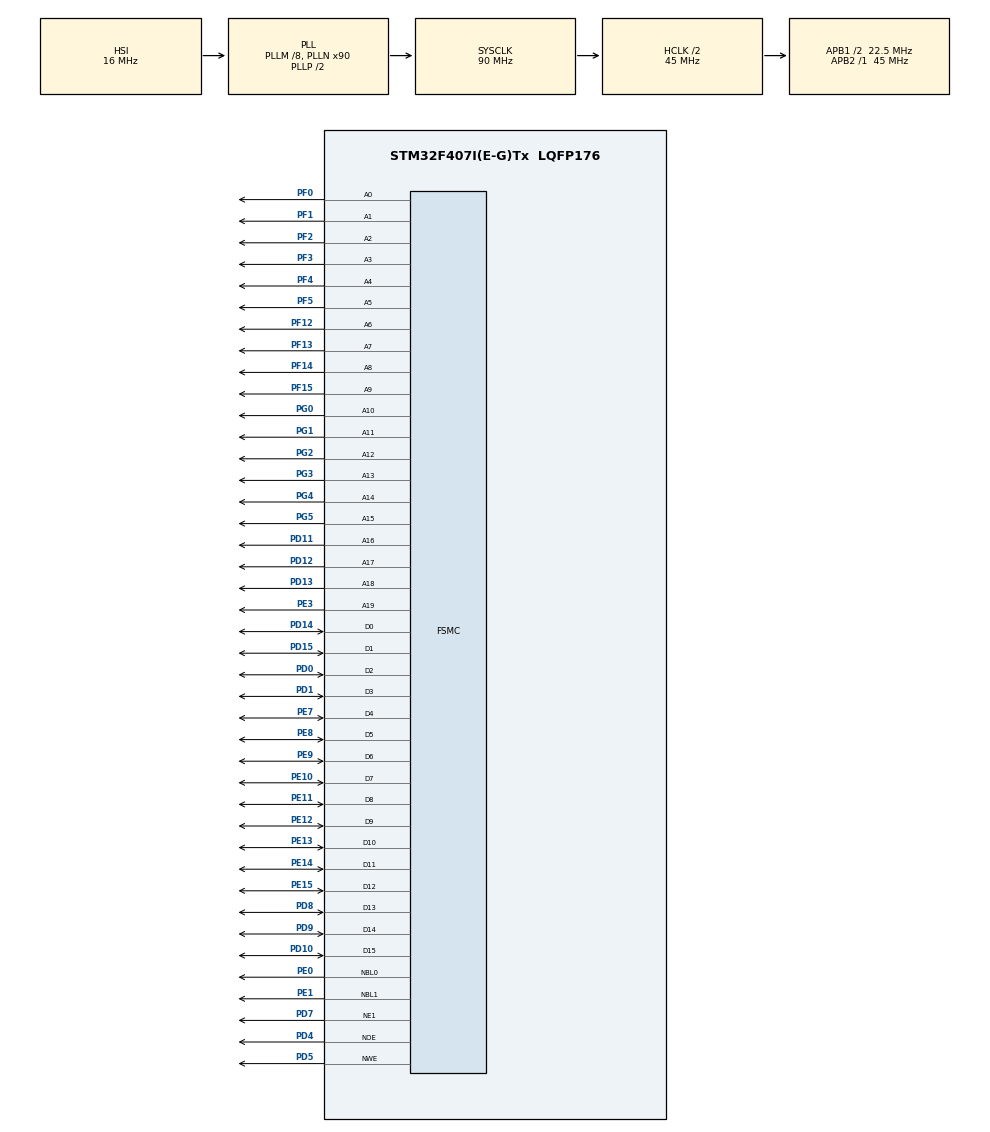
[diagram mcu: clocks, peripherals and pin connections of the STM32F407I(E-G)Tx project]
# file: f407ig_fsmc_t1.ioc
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FSMC.ExtendedMode1=FSMC_EXTENDED_MODE_DISABLE
FSMC.WriteOperation1=FSMC_WRITE_OPERATION_ENABLE
Mcu.Family=STM32F4
Mcu.Name=STM32F407I(E-G)Tx
Mcu.Package=LQFP176
NVIC.PriorityGroup=NVIC_PRIORITYGROUP_4
PA13.Mode=Trace_Asynchronous_SW
PA13.Signal=SYS_JTMS-SWDIO
PA14.Mode=Trace_Asynchronous_SW
PA14.Signal=SYS_JTCK-SWCLK
PB3.Mode=Trace_Asynchronous_SW
PB3.Signal=SYS_JTDO-SWO
PC14-OSC32_IN.Mode=LSE-External-Oscillator
PC14-OSC32_IN.Signal=RCC_OSC32_IN
PC15-OSC32_OUT.Mode=LSE-External-Oscillator
PC15-OSC32_OUT.Signal=RCC_OSC32_OUT
PD0.Signal=FSMC_D2_DA2
PD1.Signal=FSMC_D3_DA3
PD10.Signal=FSMC_D15_DA15
PD11.Signal=FSMC_A16_CLE
PD12.Signal=FSMC_A17_ALE
PD13.Signal=FSMC_A18
PD14.Signal=FSMC_D0_DA0
PD15.Signal=FSMC_D1_DA1
PD4.Signal=FSMC_NOE
PD5.Signal=FSMC_NWE
PD7.Mode=NorPsramChipSelect1_1
PD7.Signal=FSMC_NE1
PD8.Signal=FSMC_D13_DA13
PD9.Signal=FSMC_D14_DA14
PE0.Signal=FSMC_NBL0
PE1.Signal=FSMC_NBL1
PE10.Signal=FSMC_D7_DA7
PE11.Signal=FSMC_D8_DA8
PE12.Signal=FSMC_D9_DA9
PE13.Signal=FSMC_D10_DA10
PE14.Signal=FSMC_D11_DA11
PE15.Signal=FSMC_D12_DA12
PE3.Signal=FSMC_A19
PE7.Signal=FSMC_D4_DA4
PE8.Signal=FSMC_D5_DA5
PE9.Signal=FSMC_D6_DA6
PF0.Signal=FSMC_A0
PF1.Signal=FSMC_A1
PF12.Signal=FSMC_A6
PF13.Signal=FSMC_A7
PF14.Signal=FSMC_A8
PF15.Signal=FSMC_A9
PF2.Signal=FSMC_A2
PF3.Signal=FSMC_A3
PF4.Signal=FSMC_A4
PF5.Signal=FSMC_A5
PG0.Signal=FSMC_A10
PG1.Signal=FSMC_A11
PG2.Signal=FSMC_A12
PG3.Signal=FSMC_A13
PG4.Signal=FSMC_A14
PG5.Signal=FSMC_A15
PH0-OSC_IN.Mode=HSE-External-Oscillator
PH0-OSC_IN.Signal=RCC_OSC_IN
PH1-OSC_OUT.Mode=HSE-External-Oscillator
PH1-OSC_OUT.Signal=RCC_OSC_OUT
ProjectManager.HeapSize=0x200
ProjectManager.StackSize=0x400
ProjectManager.TargetToolchain=MDK-ARM V5
RCC.48MHZClocksFreq_Value=45000000
RCC.AHBCLKDivider=RCC_SYSCLK_DIV2
RCC.AHBFreq_Value=45000000
RCC.APB1CLKDivider=RCC_HCLK_DIV2
RCC.APB1Freq_Value=22500000
RCC.APB1TimFreq_Value=45000000
RCC.APB2Freq_Value=45000000
RCC.APB2TimFreq_Value=45000000
RCC.CortexFreq_Value=45000000
RCC.HCLKFreq_Value=45000000
RCC.HSE_VALUE=8000000
RCC.HSI_VALUE=16000000
RCC.PLLM=8
RCC.PLLN=90
RCC.SYSCLKFreq_VALUE=90000000
RCC.SYSCLKSource=RCC_SYSCLKSOURCE_PLLCLK
RCC.VCOOutputFreq_Value=180000000
SH.FSMC_A0.0=FSMC_A0,20b-a1
SH.FSMC_A1.0=FSMC_A1,20b-a1
SH.FSMC_A10.0=FSMC_A10,20b-a1
SH.FSMC_A11.0=FSMC_A11,20b-a1
SH.FSMC_A12.0=FSMC_A12,20b-a1
SH.FSMC_A13.0=FSMC_A13,20b-a1
SH.FSMC_A14.0=FSMC_A14,20b-a1
SH.FSMC_A15.0=FSMC_A15,20b-a1
SH.FSMC_A16_CLE.0=FSMC_A16,20b-a1
SH.FSMC_A17_ALE.0=FSMC_A17,20b-a1
SH.FSMC_A18.0=FSMC_A18,20b-a1
SH.FSMC_A19.0=FSMC_A19,20b-a1
SH.FSMC_A2.0=FSMC_A2,20b-a1
SH.FSMC_A3.0=FSMC_A3,20b-a1
SH.FSMC_A4.0=FSMC_A4,20b-a1
SH.FSMC_A5.0=FSMC_A5,20b-a1
SH.FSMC_A6.0=FSMC_A6,20b-a1
SH.FSMC_A7.0=FSMC_A7,20b-a1
SH.FSMC_A8.0=FSMC_A8,20b-a1
SH.FSMC_A9.0=FSMC_A9,20b-a1
SH.FSMC_D0_DA0.0=FSMC_D0,16b-d1
SH.FSMC_D10_DA10.0=FSMC_D10,16b-d1
SH.FSMC_D11_DA11.0=FSMC_D11,16b-d1
SH.FSMC_D12_DA12.0=FSMC_D12,16b-d1
SH.FSMC_D13_DA13.0=FSMC_D13,16b-d1
SH.FSMC_D14_DA14.0=FSMC_D14,16b-d1
SH.FSMC_D15_DA15.0=FSMC_D15,16b-d1
SH.FSMC_D1_DA1.0=FSMC_D1,16b-d1
SH.FSMC_D2_DA2.0=FSMC_D2,16b-d1
SH.FSMC_D3_DA3.0=FSMC_D3,16b-d1
SH.FSMC_D4_DA4.0=FSMC_D4,16b-d1
SH.FSMC_D5_DA5.0=FSMC_D5,16b-d1
SH.FSMC_D6_DA6.0=FSMC_D6,16b-d1
SH.FSMC_D7_DA7.0=FSMC_D7,16b-d1
SH.FSMC_D8_DA8.0=FSMC_D8,16b-d1
SH.FSMC_D9_DA9.0=FSMC_D9,16b-d1
SH.FSMC_NBL0.0=FSMC_NBL0,2ByteEnable1
SH.FSMC_NBL1.0=FSMC_NBL1,2ByteEnable1
SH.FSMC_NOE.0=FSMC_NOE,Sram1
SH.FSMC_NWE.0=FSMC_NWE,Sram1
board=f407ig_fsmc_t1

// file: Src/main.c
/**
  ******************************************************************************
  * File Name          : main.c
  * Description        : Main program body
  ******************************************************************************
  ** This notice applies to any and all portions of this file
  * that are not between comment pairs USER CODE BEGIN and
  * USER CODE END. Other portions of this file, whether
  * inserted by the user or by software development tools
  * are owned by their respective copyright owners.
  *
  * COPYRIGHT(c) 2017 STMicroelectronics
  *
  * Redistribution and use in source and binary forms, with or without modification,
  * are permitted provided that the following conditions are met:
  *   1. Redistributions of source code must retain the above copyright notice,
  *      this list of conditions and the following disclaimer.
  *   2. Redistributions in binary form must reproduce the above copyright notice,
  *      this list of conditions and the following disclaimer in the documentation
  *      and/or other materials provided with the distribution.
  *   3. Neither the name of STMicroelectronics nor the names of its contributors
  *      may be used to endorse or promote products derived from this software
  *      without specific prior written permission.
  *
  * THIS SOFTWARE IS PROVIDED BY THE COPYRIGHT HOLDERS AND CONTRIBUTORS "AS IS"
  * AND ANY EXPRESS OR IMPLIED WARRANTIES, INCLUDING, BUT NOT LIMITED TO, THE
  * IMPLIED WARRANTIES OF MERCHANTABILITY AND FITNESS FOR A PARTICULAR PURPOSE ARE
  * DISCLAIMED. IN NO EVENT SHALL THE COPYRIGHT HOLDER OR CONTRIBUTORS BE LIABLE
  * FOR ANY DIRECT, INDIRECT, INCIDENTAL, SPECIAL, EXEMPLARY, OR CONSEQUENTIAL
  * DAMAGES (INCLUDING, BUT NOT LIMITED TO, PROCUREMENT OF SUBSTITUTE GOODS OR
  * SERVICES; LOSS OF USE, DATA, OR PROFITS; OR BUSINESS INTERRUPTION) HOWEVER
  * CAUSED AND ON ANY THEORY OF LIABILITY, WHETHER IN CONTRACT, STRICT LIABILITY,
  * OR TORT (INCLUDING NEGLIGENCE OR OTHERWISE) ARISING IN ANY WAY OUT OF THE USE
  * OF THIS SOFTWARE, EVEN IF ADVISED OF THE POSSIBILITY OF SUCH DAMAGE.
  *
  ******************************************************************************
  */
#include "main.h"
#include "stm32f4xx_hal.h"
#include "gpio.h"
#include "fsmc.h"

/* USER CODE BEGIN PV */
/* Private variables ---------------------------------------------------------*/

/* USER CODE END PV */

void SystemClock_Config(void);

/* USER CODE BEGIN PFP */
/* Private function prototypes -----------------------------------------------*/

/* USER CODE END PFP */

int main(void)
{

  /* MCU Configuration----------------------------------------------------------*/

  /* Reset of all peripherals, Initializes the Flash interface and the Systick. */
  HAL_Init();

  /* Configure the system clock */
  SystemClock_Config();

  /* Initialize all configured peripherals */
  MX_GPIO_Init();
  MX_FSMC_Init();

  /* Infinite loop */
  /* USER CODE BEGIN WHILE */
  while (1)
  {
#define BANK1_BASE	(0x60000000)

		printf("Test Start %u\n", SystemCoreClock);
		HAL_Delay(1000);

		//Write
		for(uint32_t i=0; i<2000; i+=sizeof(uint8_t))
		{
			*((uint8_t*)(BANK1_BASE+i)) = i;
			printf("%08X->%08X\n", i, *((uint8_t*)(BANK1_BASE+i)));
		}

		HAL_Delay(1000);

		//Read
		for(uint32_t i=0; i<2000; i+=sizeof(uint8_t))
		{
			printf("%08X->%08X\n", i, *((uint8_t*)(BANK1_BASE+i)));
		}
		HAL_Delay(1000);
  /* USER CODE END WHILE */

  }

}

/** System Clock Configuration
*/
void SystemClock_Config(void)
{

  RCC_OscInitTypeDef RCC_OscInitStruct;
  RCC_ClkInitTypeDef RCC_ClkInitStruct;

    /**Configure the main internal regulator output voltage
    */
  __HAL_RCC_PWR_CLK_ENABLE();

  __HAL_PWR_VOLTAGESCALING_CONFIG(PWR_REGULATOR_VOLTAGE_SCALE1);

    /**Initializes the CPU, AHB and APB busses clocks
    */
  RCC_OscInitStruct.OscillatorType = RCC_OSCILLATORTYPE_HSI;
  RCC_OscInitStruct.HSIState = RCC_HSI_ON;
  RCC_OscInitStruct.HSICalibrationValue = 16;
  RCC_OscInitStruct.PLL.PLLState = RCC_PLL_ON;
  RCC_OscInitStruct.PLL.PLLSource = RCC_PLLSOURCE_HSI;
  RCC_OscInitStruct.PLL.PLLM = 8;
  RCC_OscInitStruct.PLL.PLLN = 90;
  RCC_OscInitStruct.PLL.PLLP = RCC_PLLP_DIV2;
  RCC_OscInitStruct.PLL.PLLQ = 4;
  if (HAL_RCC_OscConfig(&RCC_OscInitStruct) != HAL_OK)
  {
    _Error_Handler(__FILE__, __LINE__);
  }

    /**Initializes the CPU, AHB and APB busses clocks
    */
  RCC_ClkInitStruct.ClockType = RCC_CLOCKTYPE_HCLK|RCC_CLOCKTYPE_SYSCLK
                              |RCC_CLOCKTYPE_PCLK1|RCC_CLOCKTYPE_PCLK2;
  RCC_ClkInitStruct.SYSCLKSource = RCC_SYSCLKSOURCE_PLLCLK;
  RCC_ClkInitStruct.AHBCLKDivider = RCC_SYSCLK_DIV2;
  RCC_ClkInitStruct.APB1CLKDivider = RCC_HCLK_DIV2;
  RCC_ClkInitStruct.APB2CLKDivider = RCC_HCLK_DIV1;

  if (HAL_RCC_ClockConfig(&RCC_ClkInitStruct, FLASH_LATENCY_1) != HAL_OK)
  {
    _Error_Handler(__FILE__, __LINE__);
  }

    /**Configure the Systick interrupt time
    */
  HAL_SYSTICK_Config(HAL_RCC_GetHCLKFreq()/1000);

    /**Configure the Systick
    */
  HAL_SYSTICK_CLKSourceConfig(SYSTICK_CLKSOURCE_HCLK);

  /* SysTick_IRQn interrupt configuration */
  HAL_NVIC_SetPriority(SysTick_IRQn, 0, 0);
}

void _Error_Handler(char * file, int line)
{
  while(1)
  {
  }
}

/************************ (C) COPYRIGHT STMicroelectronics *****END OF FILE****/
